# M481_v1 register map
File version: 1.0
Registers are 32-bit, read-write, reset 0x0 unless marked. A register's access mark holds for its fields unless they carry their own. Offsets are from the block's base; [hi:lo] are bit positions; {n}, {i} and the like mark numbered series.

## NVIC — NVIC Register Map
Base 0xE000E100
{0x0+4i} NVIC_ISER{i} (i=0..3) — IRQ0 ~ IRQ108 Set-enable Control Register
  [31:0] SETENA — Interrupt Set Enable Bit. The NVIC_ISER0-NVIC_ISER3 registers enable interrupts, and show which interrupts are enabled. Write Operation:
    0=No effect. Interrupt Disabled; 1=Interrupt Enabled
{0x80+4i} NVIC_ICER{i} (i=0..3) — IRQ0 ~ IRQ108 Clear-enable Control Register
  [31:0] CALENA — Interrupt Clear Enable Bit. The NVIC_ICER0-NVIC_ICER3 registers disable interrupts, and show which interrupts are enabled. Write Operation:
    0=No effect. Interrupt Disabled; 1=Interrupt Disabled. Interrupt Enabled
{0x100+4i} NVIC_ISPR{i} (i=0..3) — IRQ0 ~ IRQ108 Set-pending Control Register
  [31:0] SETPEND — Interrupt Set-pending. The NVIC_ISPR0-NVIC_ISPR3 registers force interrupts into the pending state, and show which interrupts are pending. Write Operation:
    0=No effect. Interrupt is not pending; 1=Changes interrupt state to pending. Interrupt is pending
{0x180+4i} NVIC_ICPR{i} (i=0..3) — IRQ0 ~ IRQ108 Clear-pending Control Register
  [31:0] CALPEND — Interrupt Clear-pending. The NVIC_ICPR0-NVIC_ICPR3 registers remove the pending state from interrupts, and show which interrupts are pending. Write Operation:
    0=No effect. Interrupt is not pending; 1=Removes pending state an interrupt. Interrupt is pending
{0x200+4i} NVIC_IABR{i} (i=0..3) — IRQ0 ~ IRQ108 Active Bit Register
  [31:0] ACTIVE — Interrupt Active Flags. The NVIC_IABR0-NVIC_IABR3 registers indicate which interrupts are active.
    0=interrupt not active; 1=interrupt active
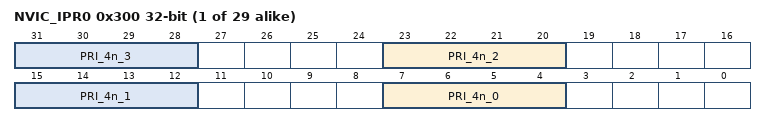
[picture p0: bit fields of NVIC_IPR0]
{0x300+4i} NVIC_IPR{i} (i=0..28) — IRQ0 ~ IRQ71 Priority Control Register
  [8n+7:8n+4] PRI_4n_{n} (n=0..3) — Priority of IRQ_4n+{n} '0' denotes the highest priority and '15' denotes the lowest priority
0xE00 STIR — Software Trigger Interrupt Registers
  [8:0] INTID — Interrupt ID. Write to the STIR To Generate An Interrupt from Software. When the USERSETMPEND bit in the SCR is set to 1, unprivileged software can access the STIR. Interrupt ID of the interrupt to trigger, in the range 0-63. For example, a value of 0x03 specifies interrupt IRQ3.

## AHB — AHB Register Map
Base 0x40000400
0x00 AHBMCTL reset 0x1 — AHB Bus Matrix Priority Control Register
  [0] INTACTEN — Highest AHB Bus Priority of Cortex®-M4 Core Enable Bit (Write Protect). Enable Cortex®-M4 Core With Highest AHB Bus Priority In AHB Bus Matrix. Note: This bit is write protected. Refer to the SYS_REGLCTL register.
    0=Run robin mode; 1=Cortex®-M4 CPU with highest bus priority when interrupt occusr

## TRNG — TRNG Register Map
Base 0x400B9000
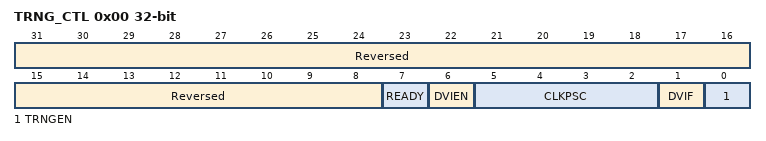
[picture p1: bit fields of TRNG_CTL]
0x00 TRNG_CTL — TRNG Control Register and Status
  [31:8] Reversed
  [7] READY ro — Random Number Generator Ready (Read Only). After ACT (TRNG_ACT[7]) bit is set, the READY bit become to 1 after a delay of 90us~120us.
    0=RNG is not ready or activated; 1=RNG is ready to be enabled
  [6] DVIEN — Data Valid Interrupt Enable Bit
    0=Interrupt Disabled; 1=Interrupt Enabled
  [5:2] CLKPSC — Clock Prescaler. The CLKPSC is the peripheral clock frequency range for the selected value , the CLKPSC setting must be higher than or equal to the actual peripheral clock frequency (for correct random bit generation). To change the CLKPSC setting, set TRNGEN bit to 0, change CLKPSC, and set TRNGEN bit to 1 to re-enable the TRNG.
    0=80 ~ 100 MHz; 1=60 ~ 80 MHz; 2=50 ~60 MHz; 3=40 ~50 MHz; 4=30 ~40 MHz; 5=25 ~30 MHz; 6=20 ~25 MHz; 7=15 ~20 MHz; 8=12 ~15 MHz; 9=9 ~12 MHz; 10=7 ~9 MHz; 11=6 ~7 MHz; 12=5 ~6 MHz; 13=4 ~5 MHz
  [1] DVIF ro — Data Valid (Read Only). Note: This bit is cleared to '0' by reading TRNG_DATA.
    0=Data is not valid. Reading from RNGD returns 0x00000000; 1=Data is valid. A valid random number can be read form DATA(TRNG_DATA[7:0])
  [0] TRNGEN — Random Number Generator Enable Bit. This bit can be set to 1 only after ACT (TRNG_ACT[7]) bit is set to 1 and READY (TRNG_CTL[7]) bit became 1. Note: TRNGEN is an enable bit of digital part. When TRNG is not required to generate random number, TRNGEN bit and ACT (TRNG_ACT[7]) bit should be set to 0 to reduce power consumption.
    0=TRNG Disabled; 1=TRNG Enabled
0x04 TRNG_DATA ro
  [7:0] DATA — Random Number Generator Data (Read Only). The DATA store the random number is generated by TRNG and can be read only once.
0x0C TRNG_ACT reset 0x2 — TRNG Activation Register
  [7] ACT — Random Number Generator Activation. After enable the ACT bit, it will active the TRNG module and wait the READY (TRNG_CTL[7]) bit to become 1. Note: ACT is an enable bit of analog part. When TRNG is not required to generate random number, TRNGEN (TRNG_CTL[0]) bit and ACT bit should be set to 0 to reduce power consumption.
    0=TRNG inactive; 1=TRNG active
